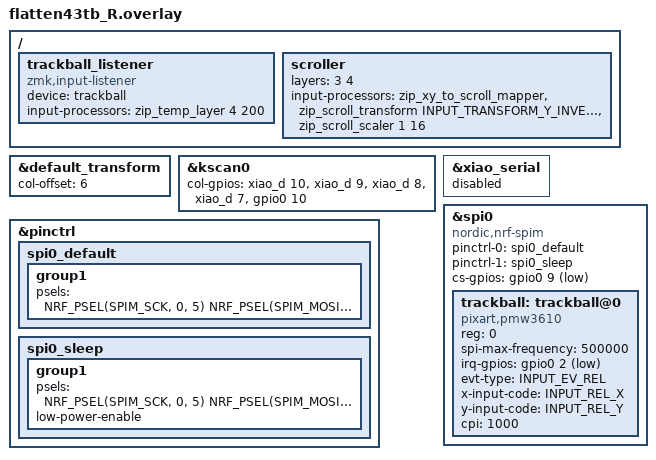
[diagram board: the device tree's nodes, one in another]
#include "flatten43tb.dtsi"
#include <zephyr/dt-bindings/input/input-event-codes.h>
#include <dt-bindings/zmk/input_transform.h>
#include <input/processors.dtsi>

/* =========================
 * Root
 * ========================= */
 / {
 };

/* =========================
 * Default transform
 * ========================= */
&default_transform {
    /* 物理配列に合わせて元の値を維持 */
    col-offset = <6>;
};

/* =========================
 * Key scan
 * ========================= */
&kscan0 {
    col-gpios
        = <&xiao_d 10 GPIO_ACTIVE_HIGH>
        , <&xiao_d 9  GPIO_ACTIVE_HIGH>
        , <&xiao_d 8  GPIO_ACTIVE_HIGH>
        , <&xiao_d 7  GPIO_ACTIVE_HIGH>
        , <&gpio0 10 GPIO_ACTIVE_HIGH>
        ;
};

/* =========================
 * Trackball input pipeline
 * ========================= */
 / {
    trackball_listener {
        status = "okay";
        compatible = "zmk,input-listener";
        device = <&trackball>;

        /* Auto mouse layer = 4 (200ms timeout) */
        input-processors = <
            &zip_temp_layer 4 200
        >;
    };

    scroller {
        /* Scroll works on scroll-layer + mouse-layer */
        layers = <3 4>;
        input-processors = <
            &zip_xy_to_scroll_mapper
            &zip_scroll_transform INPUT_TRANSFORM_Y_INVERT
            &zip_scroll_scaler 1 16
        >;
    };
};

/* =========================
 * SPI pin control (STABLE / HALF-DUPLEX)
 * ========================= */
&pinctrl {
    spi0_default: spi0_default {
        group1 {
            psels = <
                NRF_PSEL(SPIM_SCK,  0, 5)
                NRF_PSEL(SPIM_MOSI, 0, 4)
                /* MOSI/MISO共通（基板配線に合わせる） */
                NRF_PSEL(SPIM_MISO, 0, 4)
            >;
        };
    };

    spi0_sleep: spi0_sleep {
        group1 {
            psels = <
                NRF_PSEL(SPIM_SCK,  0, 5)
                NRF_PSEL(SPIM_MOSI, 0, 4)
                NRF_PSEL(SPIM_MISO, 0, 4)
            >;
            low-power-enable;
        };
    };
};

/* =========================
 * Disable serial
 * ========================= */
&xiao_serial {
    status = "disabled";
};

/* =========================
 * SPI + Trackball device
 * ========================= */
&spi0 {
    status = "okay";
    compatible = "nordic,nrf-spim";
    pinctrl-0 = <&spi0_default>;
    pinctrl-1 = <&spi0_sleep>;
    pinctrl-names = "default", "sleep";

    /* 基板既定のCS/IRQを維持 */
    cs-gpios = <&gpio0 9 GPIO_ACTIVE_LOW>;

    trackball: trackball@0 {
        status = "okay";
        compatible = "pixart,pmw3610";
        reg = <0>;

        /* 実用安定重視：通信を低速化 */
        spi-max-frequency = <500000>;

        irq-gpios = <&gpio0 2 (GPIO_ACTIVE_LOW | GPIO_PULL_UP)>;

        evt-type = <INPUT_EV_REL>;
        x-input-code = <INPUT_REL_X>;
        y-input-code = <INPUT_REL_Y>;

        /* 初動と誤爆のバランスが良い値 */
        cpi = <1000>;
    };
};
